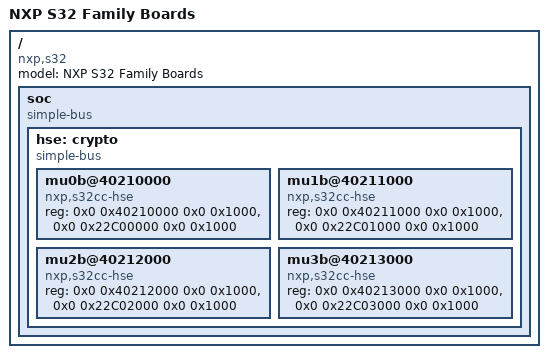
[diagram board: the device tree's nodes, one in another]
// SPDX-License-Identifier: BSD-3-Clause
/*
 * Copyright 2022 NXP
 */
/dts-v1/;

/ {
	model = "NXP S32 Family Boards";
	compatible = "nxp,s32";
	#address-cells = <2>;
	#size-cells = <2>;

	soc {
		compatible = "simple-bus";
		#address-cells = <2>;
		#size-cells = <2>;
		ranges = <0x0 0x0 0x0 0x0 0x0 0x20000000>,
			 <0x0 0x22C00000 0x0 0x22C00000 0x0 0x4000>,
			 <0x0 0x40000000 0x0 0x40000000 0x0 0x14000000>,
			 <0x48 0x0 0x48 0x0 0x8 0x0>,
			 <0x58 0x0 0x58 0x0 0x8 0x0>;

		hse: crypto {
			compatible = "simple-bus";
			#address-cells = <2>;
			#size-cells = <2>;
			ranges;

			mu0b@40210000 {
				compatible = "nxp,s32cc-hse";
				reg = <0x0 0x40210000 0x0 0x1000>,
				<0x0 0x22C00000 0x0 0x1000>;
				reg-names = "hse-mu0b-regs",
					"hse-mu0b-desc";
			};
			mu1b@40211000 {
				compatible = "nxp,s32cc-hse";
				reg = <0x0 0x40211000 0x0 0x1000>,
				<0x0 0x22C01000 0x0 0x1000>;
				reg-names = "hse-mu1b-regs",
					"hse-mu1b-desc";
			};
			mu2b@40212000 {
				compatible = "nxp,s32cc-hse";
				reg = <0x0 0x40212000 0x0 0x1000>,
				<0x0 0x22C02000 0x0 0x1000>;
				reg-names = "hse-mu2b-regs",
					"hse-mu2b-desc";
			};
			mu3b@40213000 {
				compatible = "nxp,s32cc-hse";
				reg = <0x0 0x40213000 0x0 0x1000>,
				<0x0 0x22C03000 0x0 0x1000>;
				reg-names = "hse-mu3b-regs",
					"hse-mu3b-desc";
			};
		};
	};
};
